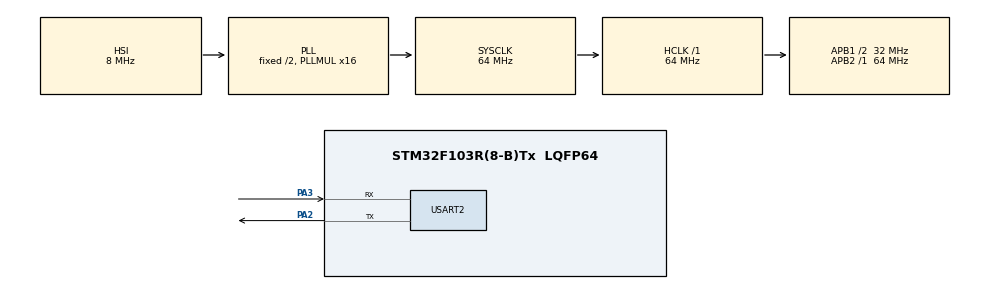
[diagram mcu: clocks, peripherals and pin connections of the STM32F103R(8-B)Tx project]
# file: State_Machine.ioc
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Mcu.Family=STM32F1
Mcu.Name=STM32F103R(8-B)Tx
Mcu.Package=LQFP64
NVIC.PriorityGroup=NVIC_PRIORITYGROUP_4
PA2.Mode=Asynchronous
PA2.Signal=USART2_TX
PA3.Mode=Asynchronous
PA3.Signal=USART2_RX
ProjectManager.HeapSize=0x2000
ProjectManager.StackSize=0x400
ProjectManager.TargetToolchain=MDK-ARM V5
RCC.AHBFreq_Value=64000000
RCC.APB1CLKDivider=RCC_HCLK_DIV2
RCC.APB1Freq_Value=32000000
RCC.APB1TimFreq_Value=64000000
RCC.APB2Freq_Value=64000000
RCC.APB2TimFreq_Value=64000000
RCC.HCLKFreq_Value=64000000
RCC.PLLMUL=RCC_PLL_MUL16
RCC.RTCClockSelection=RCC_RTCCLKSOURCE_LSE
RCC.SYSCLKFreq_VALUE=64000000
RCC.SYSCLKSource=RCC_SYSCLKSOURCE_PLLCLK
RCC.USBFreq_Value=64000000
USART2.VirtualMode=VM_ASYNC
VP_SYS_VS_ND.Mode=No_Debug
board=NUCLEO-F103RB

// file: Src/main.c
/* USER CODE BEGIN Header */
/**
  ******************************************************************************
  * @file           : main.c
  * @brief          : ACS state machine main file
  ******************************************************************************
  ** This file contains the ACS flight software used on SlugSat's flat-sat. This
	* program is designed to run in conjunction with SlugSat's 42 simulation to
	* show the behavior of the full ACS.
  ******************************************************************************
  */
/* USER CODE END Header */

#include "main.h"

/* USER CODE BEGIN Includes */
// ACS modules
#include <ACSStateMachine.h>

/* USER CODE END Includes */

UART_HandleTypeDef huart2;

void SystemClock_Config(void);
static void MX_GPIO_Init(void);
static void MX_USART2_UART_Init(void);

int main(void)
{

  /* MCU Configuration--------------------------------------------------------*/

  /* Reset of all peripherals, Initializes the Flash interface and the Systick. */
  HAL_Init();

  /* Configure the system clock */
  SystemClock_Config();

  /* Initialize all configured peripherals */
  MX_GPIO_Init();
  MX_USART2_UART_Init();
  /* USER CODE BEGIN 2 */

	setUartHandle(&huart2);
	runACS();

  /* USER CODE END 2 */

  /* Infinite loop */
  while (1)
  {

	}
}

void SystemClock_Config(void)
{
  RCC_OscInitTypeDef RCC_OscInitStruct = {0};
  RCC_ClkInitTypeDef RCC_ClkInitStruct = {0};

  /** Initializes the CPU, AHB and APB busses clocks
  */
  RCC_OscInitStruct.OscillatorType = RCC_OSCILLATORTYPE_HSI;
  RCC_OscInitStruct.HSIState = RCC_HSI_ON;
  RCC_OscInitStruct.HSICalibrationValue = RCC_HSICALIBRATION_DEFAULT;
  RCC_OscInitStruct.PLL.PLLState = RCC_PLL_ON;
  RCC_OscInitStruct.PLL.PLLSource = RCC_PLLSOURCE_HSI_DIV2;
  RCC_OscInitStruct.PLL.PLLMUL = RCC_PLL_MUL16;
  if (HAL_RCC_OscConfig(&RCC_OscInitStruct) != HAL_OK)
  {
    Error_Handler();
  }
  /** Initializes the CPU, AHB and APB busses clocks
  */
  RCC_ClkInitStruct.ClockType = RCC_CLOCKTYPE_HCLK|RCC_CLOCKTYPE_SYSCLK
                              |RCC_CLOCKTYPE_PCLK1|RCC_CLOCKTYPE_PCLK2;
  RCC_ClkInitStruct.SYSCLKSource = RCC_SYSCLKSOURCE_PLLCLK;
  RCC_ClkInitStruct.AHBCLKDivider = RCC_SYSCLK_DIV1;
  RCC_ClkInitStruct.APB1CLKDivider = RCC_HCLK_DIV2;
  RCC_ClkInitStruct.APB2CLKDivider = RCC_HCLK_DIV1;

  if (HAL_RCC_ClockConfig(&RCC_ClkInitStruct, FLASH_LATENCY_2) != HAL_OK)
  {
    Error_Handler();
  }
}

static void MX_USART2_UART_Init(void)
{

  huart2.Instance = USART2;
  huart2.Init.BaudRate = 115200;
  huart2.Init.WordLength = UART_WORDLENGTH_8B;
  huart2.Init.StopBits = UART_STOPBITS_1;
  huart2.Init.Parity = UART_PARITY_NONE;
  huart2.Init.Mode = UART_MODE_TX_RX;
  huart2.Init.HwFlowCtl = UART_HWCONTROL_NONE;
  huart2.Init.OverSampling = UART_OVERSAMPLING_16;
  if (HAL_UART_Init(&huart2) != HAL_OK)
  {
    Error_Handler();
  }

}

static void MX_GPIO_Init(void)
{

  /* GPIO Ports Clock Enable */
  __HAL_RCC_GPIOA_CLK_ENABLE();

}

/* USER CODE BEGIN 4 */

//void LoadProcessor(uint8_t time_ms)
//{
//	uint16_t init_time = TIM2->CNT;
//	uint16_t delay_time_10us = time_ms*100;
//
//	v = (float)rand()/(float)rand();
//
//	while((uint16_t)(TIM2->CNT - init_time) < delay_time_10us) {
//		v = v*(float)rand()/(float)rand();
//	}
//}

/* USER CODE END 4 */

void Error_Handler(void)
{
}

/************************ (C) COPYRIGHT STMicroelectronics *****END OF FILE****/
